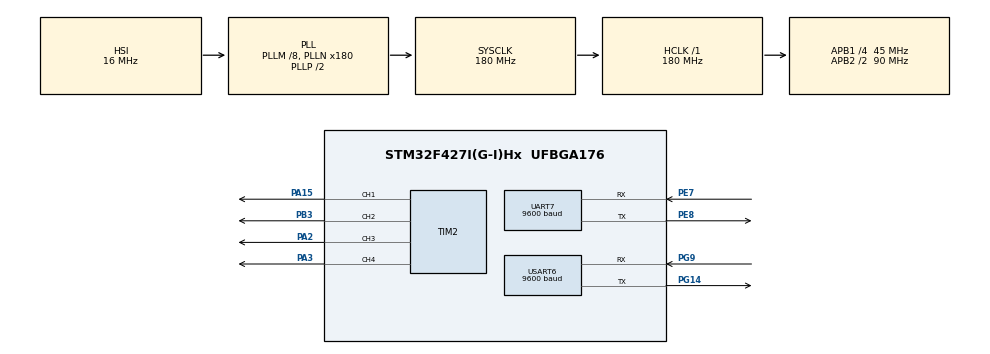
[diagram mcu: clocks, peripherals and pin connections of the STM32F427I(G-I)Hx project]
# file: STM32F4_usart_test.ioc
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Dma.Request0=USART6_RX
Dma.Request1=USART6_TX
Dma.Request2=UART7_RX
Dma.Request3=UART7_TX
Dma.UART7_RX.2.Direction=DMA_PERIPH_TO_MEMORY
Dma.UART7_RX.2.FIFOMode=DMA_FIFOMODE_DISABLE
Dma.UART7_RX.2.Instance=DMA1_Stream3
Dma.UART7_RX.2.MemDataAlignment=DMA_MDATAALIGN_BYTE
Dma.UART7_RX.2.MemInc=DMA_MINC_ENABLE
Dma.UART7_RX.2.Mode=DMA_NORMAL
Dma.UART7_RX.2.PeriphDataAlignment=DMA_PDATAALIGN_BYTE
Dma.UART7_RX.2.PeriphInc=DMA_PINC_DISABLE
Dma.UART7_RX.2.Priority=DMA_PRIORITY_LOW
Dma.UART7_TX.3.Direction=DMA_MEMORY_TO_PERIPH
Dma.UART7_TX.3.FIFOMode=DMA_FIFOMODE_DISABLE
Dma.UART7_TX.3.Instance=DMA1_Stream1
Dma.UART7_TX.3.MemDataAlignment=DMA_MDATAALIGN_BYTE
Dma.UART7_TX.3.MemInc=DMA_MINC_ENABLE
Dma.UART7_TX.3.Mode=DMA_NORMAL
Dma.UART7_TX.3.PeriphDataAlignment=DMA_PDATAALIGN_BYTE
Dma.UART7_TX.3.PeriphInc=DMA_PINC_DISABLE
Dma.UART7_TX.3.Priority=DMA_PRIORITY_LOW
Dma.USART6_RX.0.Direction=DMA_PERIPH_TO_MEMORY
Dma.USART6_RX.0.FIFOMode=DMA_FIFOMODE_DISABLE
Dma.USART6_RX.0.Instance=DMA2_Stream1
Dma.USART6_RX.0.MemDataAlignment=DMA_MDATAALIGN_BYTE
Dma.USART6_RX.0.MemInc=DMA_MINC_ENABLE
Dma.USART6_RX.0.Mode=DMA_NORMAL
Dma.USART6_RX.0.PeriphDataAlignment=DMA_PDATAALIGN_BYTE
Dma.USART6_RX.0.PeriphInc=DMA_PINC_DISABLE
Dma.USART6_RX.0.Priority=DMA_PRIORITY_LOW
Dma.USART6_TX.1.Direction=DMA_MEMORY_TO_PERIPH
Dma.USART6_TX.1.FIFOMode=DMA_FIFOMODE_DISABLE
Dma.USART6_TX.1.Instance=DMA2_Stream6
Dma.USART6_TX.1.MemDataAlignment=DMA_MDATAALIGN_BYTE
Dma.USART6_TX.1.MemInc=DMA_MINC_ENABLE
Dma.USART6_TX.1.Mode=DMA_NORMAL
Dma.USART6_TX.1.PeriphDataAlignment=DMA_PDATAALIGN_BYTE
Dma.USART6_TX.1.PeriphInc=DMA_PINC_DISABLE
Dma.USART6_TX.1.Priority=DMA_PRIORITY_LOW
FREERTOS.Events01=EventKey1,Dynamic,NULL
FREERTOS.INCLUDE_xEventGroupSetBitFromISR=1
FREERTOS.Queues01=queuekey1,16,uint8_t,0,Dynamic,NULL,NULL
FREERTOS.Tasks01=defaultTask,24,128,StartDefaultTask,Default,NULL,Dynamic,NULL,NULL;Button_task,10,128,button_task,As external,NULL,Dynamic,NULL,NULL;Buzzer_task,9,128,buzzer_task,As external,NULL,Dynamic,NULL,NULL;LED1_task,9,128,led1_task,As external,NULL,Dynamic,NULL,NULL;LED2_task,9,128,led2_task,As external,NULL,Dynamic,NULL,NULL;LED3_task,9,128,led3_task,As external,NULL,Dynamic,NULL,NULL
Mcu.Family=STM32F4
Mcu.Name=STM32F427I(G-I)Hx
Mcu.Package=UFBGA176
NVIC.DMA1_Stream1_IRQn=true\:5\:0\:false\:false\:true\:true\:false\:true\:true
NVIC.DMA1_Stream3_IRQn=true\:5\:0\:false\:false\:true\:true\:false\:true\:true
NVIC.DMA2_Stream1_IRQn=true\:5\:0\:false\:false\:true\:true\:false\:true\:true
NVIC.DMA2_Stream6_IRQn=true\:5\:0\:false\:false\:true\:true\:false\:true\:true
NVIC.PriorityGroup=NVIC_PRIORITYGROUP_4
NVIC.TIM1_UP_TIM10_IRQn=true\:15\:0\:false\:false\:true\:false\:false\:true\:true
NVIC.TimeBase=TIM1_UP_TIM10_IRQn
NVIC.TimeBaseIP=TIM1
NVIC.UART7_IRQn=true\:5\:0\:false\:false\:true\:true\:true\:true\:true
NVIC.USART6_IRQn=true\:5\:0\:false\:false\:true\:true\:true\:true\:true
PA13.Mode=Serial_Wire
PA13.Signal=SYS_JTMS-SWDIO
PA14.Mode=Serial_Wire
PA14.Signal=SYS_JTCK-SWCLK
PA15.Signal=S_TIM2_CH1_ETR
PA2.Signal=S_TIM2_CH3
PA3.Signal=S_TIM2_CH4
PB3.Signal=S_TIM2_CH2
PD8.Signal=USART3_TX
PD9.Signal=USART3_RX
PE7.Mode=Asynchronous
PE7.Signal=UART7_RX
PE8.Mode=Asynchronous
PE8.Signal=UART7_TX
PG14.Mode=Asynchronous
PG14.Signal=USART6_TX
PG9.Mode=Asynchronous
PG9.Signal=USART6_RX
PH0/OSC_IN.Mode=HSE-External-Oscillator
PH0/OSC_IN.Signal=RCC_OSC_IN
PH1/OSC_OUT.Mode=HSE-External-Oscillator
PH1/OSC_OUT.Signal=RCC_OSC_OUT
ProjectManager.HeapSize=0x200
ProjectManager.StackSize=0x400
ProjectManager.TargetToolchain=MDK-ARM V5.32
RCC.48MHZClocksFreq_Value=90000000
RCC.AHBFreq_Value=180000000
RCC.APB1CLKDivider=RCC_HCLK_DIV4
RCC.APB1Freq_Value=45000000
RCC.APB1TimFreq_Value=90000000
RCC.APB2CLKDivider=RCC_HCLK_DIV2
RCC.APB2Freq_Value=90000000
RCC.APB2TimFreq_Value=180000000
RCC.CortexFreq_Value=180000000
RCC.HCLKFreq_Value=180000000
RCC.HSE_VALUE=25000000
RCC.HSI_VALUE=16000000
RCC.LSE_VALUE=32768
RCC.PLLM=8
RCC.PLLN=180
RCC.SYSCLKFreq_VALUE=180000000
RCC.SYSCLKSource=RCC_SYSCLKSOURCE_PLLCLK
RCC.VCOOutputFreq_Value=360000000
SH.S_TIM2_CH1_ETR.0=TIM2_CH1,PWM Generation1 CH1
SH.S_TIM2_CH2.0=TIM2_CH2,PWM Generation2 CH2
SH.S_TIM2_CH3.0=TIM2_CH3,PWM Generation3 CH3
SH.S_TIM2_CH4.0=TIM2_CH4,PWM Generation4 CH4
TIM2.Channel-PWM\ Generation1\ CH1=TIM_CHANNEL_1
TIM2.Channel-PWM\ Generation2\ CH2=TIM_CHANNEL_2
TIM2.Channel-PWM\ Generation3\ CH3=TIM_CHANNEL_3
TIM2.Channel-PWM\ Generation4\ CH4=TIM_CHANNEL_4
UART7.BaudRate=9600
UART7.VirtualMode=Asynchronous
USART6.BaudRate=9600
USART6.VirtualMode=VM_ASYNC
VP_FREERTOS_VS_CMSIS_V2.Mode=CMSIS_V2
VP_SYS_VS_tim1.Mode=TIM1
VP_TIM2_VS_ClockSourceINT.Mode=Internal
board=custom

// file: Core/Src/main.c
/* USER CODE BEGIN Header */
/**
  ******************************************************************************
  * @file           : main.c
  * @brief          : Main program body
  ******************************************************************************
  * @attention
  *
  * Copyright (c) 2024 STMicroelectronics.
  * All rights reserved.
  *
  * This software is licensed under terms that can be found in the LICENSE file
  * in the root directory of this software component.
  * If no LICENSE file comes with this software, it is provided AS-IS.
  *
  ******************************************************************************
  */
/* USER CODE END Header */
#include "main.h"
#include "cmsis_os.h"
#include "dma.h"
#include "tim.h"
#include "usart.h"
#include "gpio.h"

/* USER CODE BEGIN Includes */
#include "stdio.h"
#include "button_motor.h"

/* USER CODE END Includes */

void SystemClock_Config(void);
void MX_FREERTOS_Init(void);

int main(void)
{

  /* MCU Configuration--------------------------------------------------------*/

  /* Reset of all peripherals, Initializes the Flash interface and the Systick. */
  HAL_Init();

  /* Configure the system clock */
  SystemClock_Config();

  /* Initialize all configured peripherals */
  MX_GPIO_Init();
  MX_DMA_Init();
  MX_TIM2_Init();
  MX_USART6_UART_Init();
  MX_UART7_Init();
  /* USER CODE BEGIN 2 */

   Buttonmotorinit();

  /* USER CODE END 2 */

  /* Init scheduler */
  osKernelInitialize();  /* Call init function for freertos objects (in freertos.c) */
  MX_FREERTOS_Init();

  /* Start scheduler */
  osKernelStart();

  /* We should never get here as control is now taken by the scheduler */
  /* Infinite loop */
  while (1)
  {

  }
}

void SystemClock_Config(void)
{
  RCC_OscInitTypeDef RCC_OscInitStruct = {0};
  RCC_ClkInitTypeDef RCC_ClkInitStruct = {0};

  /** Configure the main internal regulator output voltage
  */
  __HAL_RCC_PWR_CLK_ENABLE();
  __HAL_PWR_VOLTAGESCALING_CONFIG(PWR_REGULATOR_VOLTAGE_SCALE1);

  /** Initializes the RCC Oscillators according to the specified parameters
  * in the RCC_OscInitTypeDef structure.
  */
  RCC_OscInitStruct.OscillatorType = RCC_OSCILLATORTYPE_HSI;
  RCC_OscInitStruct.HSIState = RCC_HSI_ON;
  RCC_OscInitStruct.HSICalibrationValue = RCC_HSICALIBRATION_DEFAULT;
  RCC_OscInitStruct.PLL.PLLState = RCC_PLL_ON;
  RCC_OscInitStruct.PLL.PLLSource = RCC_PLLSOURCE_HSI;
  RCC_OscInitStruct.PLL.PLLM = 8;
  RCC_OscInitStruct.PLL.PLLN = 180;
  RCC_OscInitStruct.PLL.PLLP = RCC_PLLP_DIV2;
  RCC_OscInitStruct.PLL.PLLQ = 4;
  if (HAL_RCC_OscConfig(&RCC_OscInitStruct) != HAL_OK)
  {
    Error_Handler();
  }

  /** Activate the Over-Drive mode
  */
  if (HAL_PWREx_EnableOverDrive() != HAL_OK)
  {
    Error_Handler();
  }

  /** Initializes the CPU, AHB and APB buses clocks
  */
  RCC_ClkInitStruct.ClockType = RCC_CLOCKTYPE_HCLK|RCC_CLOCKTYPE_SYSCLK
                              |RCC_CLOCKTYPE_PCLK1|RCC_CLOCKTYPE_PCLK2;
  RCC_ClkInitStruct.SYSCLKSource = RCC_SYSCLKSOURCE_PLLCLK;
  RCC_ClkInitStruct.AHBCLKDivider = RCC_SYSCLK_DIV1;
  RCC_ClkInitStruct.APB1CLKDivider = RCC_HCLK_DIV4;
  RCC_ClkInitStruct.APB2CLKDivider = RCC_HCLK_DIV2;

  if (HAL_RCC_ClockConfig(&RCC_ClkInitStruct, FLASH_LATENCY_5) != HAL_OK)
  {
    Error_Handler();
  }
}

void HAL_TIM_PeriodElapsedCallback(TIM_HandleTypeDef *htim)
{
  if (htim->Instance == TIM1) {
    HAL_IncTick();
  }
}

void Error_Handler(void)
{
  __disable_irq();
  while (1)
  {
  }
}

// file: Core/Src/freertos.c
/* USER CODE BEGIN Header */
/**
  ******************************************************************************
  * File Name          : freertos.c
  * Description        : Code for freertos applications
  ******************************************************************************
  * @attention
  *
  * Copyright (c) 2024 STMicroelectronics.
  * All rights reserved.
  *
  * This software is licensed under terms that can be found in the LICENSE file
  * in the root directory of this software component.
  * If no LICENSE file comes with this software, it is provided AS-IS.
  *
  ******************************************************************************
  */
/* USER CODE END Header */

#include "FreeRTOS.h"
#include "task.h"
#include "main.h"
#include "cmsis_os.h"

/* Definitions for defaultTask */
osThreadId_t defaultTaskHandle;
const osThreadAttr_t defaultTask_attributes = {
  .name = "defaultTask",
  .stack_size = 128 * 4,
  .priority = (osPriority_t) osPriorityNormal,
};
/* Definitions for Button_task */
osThreadId_t Button_taskHandle;
const osThreadAttr_t Button_task_attributes = {
  .name = "Button_task",
  .stack_size = 128 * 4,
  .priority = (osPriority_t) osPriorityLow2,
};
/* Definitions for Buzzer_task */
osThreadId_t Buzzer_taskHandle;
const osThreadAttr_t Buzzer_task_attributes = {
  .name = "Buzzer_task",
  .stack_size = 128 * 4,
  .priority = (osPriority_t) osPriorityLow1,
};
/* Definitions for LED1_task */
osThreadId_t LED1_taskHandle;
const osThreadAttr_t LED1_task_attributes = {
  .name = "LED1_task",
  .stack_size = 128 * 4,
  .priority = (osPriority_t) osPriorityLow1,
};
/* Definitions for LED2_task */
osThreadId_t LED2_taskHandle;
const osThreadAttr_t LED2_task_attributes = {
  .name = "LED2_task",
  .stack_size = 128 * 4,
  .priority = (osPriority_t) osPriorityLow1,
};
/* Definitions for LED3_task */
osThreadId_t LED3_taskHandle;
const osThreadAttr_t LED3_task_attributes = {
  .name = "LED3_task",
  .stack_size = 128 * 4,
  .priority = (osPriority_t) osPriorityLow1,
};
/* Definitions for queuekey1 */
osMessageQueueId_t queuekey1Handle;
const osMessageQueueAttr_t queuekey1_attributes = {
  .name = "queuekey1"
};
/* Definitions for EventKey1 */
osEventFlagsId_t EventKey1Handle;
const osEventFlagsAttr_t EventKey1_attributes = {
  .name = "EventKey1"
};

void StartDefaultTask(void *argument);
extern void button_task(void *argument);
extern void buzzer_task(void *argument);
extern void led1_task(void *argument);
extern void led2_task(void *argument);
extern void led3_task(void *argument);

void MX_FREERTOS_Init(void); /* (MISRA C 2004 rule 8.1) */

void MX_FREERTOS_Init(void) {

  /* Create the queue(s) */
  /* creation of queuekey1 */
  queuekey1Handle = osMessageQueueNew (16, sizeof(uint8_t), &queuekey1_attributes);

  /* Create the thread(s) */
  /* creation of defaultTask */
  defaultTaskHandle = osThreadNew(StartDefaultTask, NULL, &defaultTask_attributes);

  /* creation of Button_task */
  Button_taskHandle = osThreadNew(button_task, NULL, &Button_task_attributes);

  /* creation of Buzzer_task */
  Buzzer_taskHandle = osThreadNew(buzzer_task, NULL, &Buzzer_task_attributes);

  /* creation of LED1_task */
  LED1_taskHandle = osThreadNew(led1_task, NULL, &LED1_task_attributes);

  /* creation of LED2_task */
  LED2_taskHandle = osThreadNew(led2_task, NULL, &LED2_task_attributes);

  /* creation of LED3_task */
  LED3_taskHandle = osThreadNew(led3_task, NULL, &LED3_task_attributes);

  /* Create the event(s) */
  /* creation of EventKey1 */
  EventKey1Handle = osEventFlagsNew(&EventKey1_attributes);

}

void StartDefaultTask(void *argument)
{
  for(;;)
  {
    osDelay(1);
  }
}
